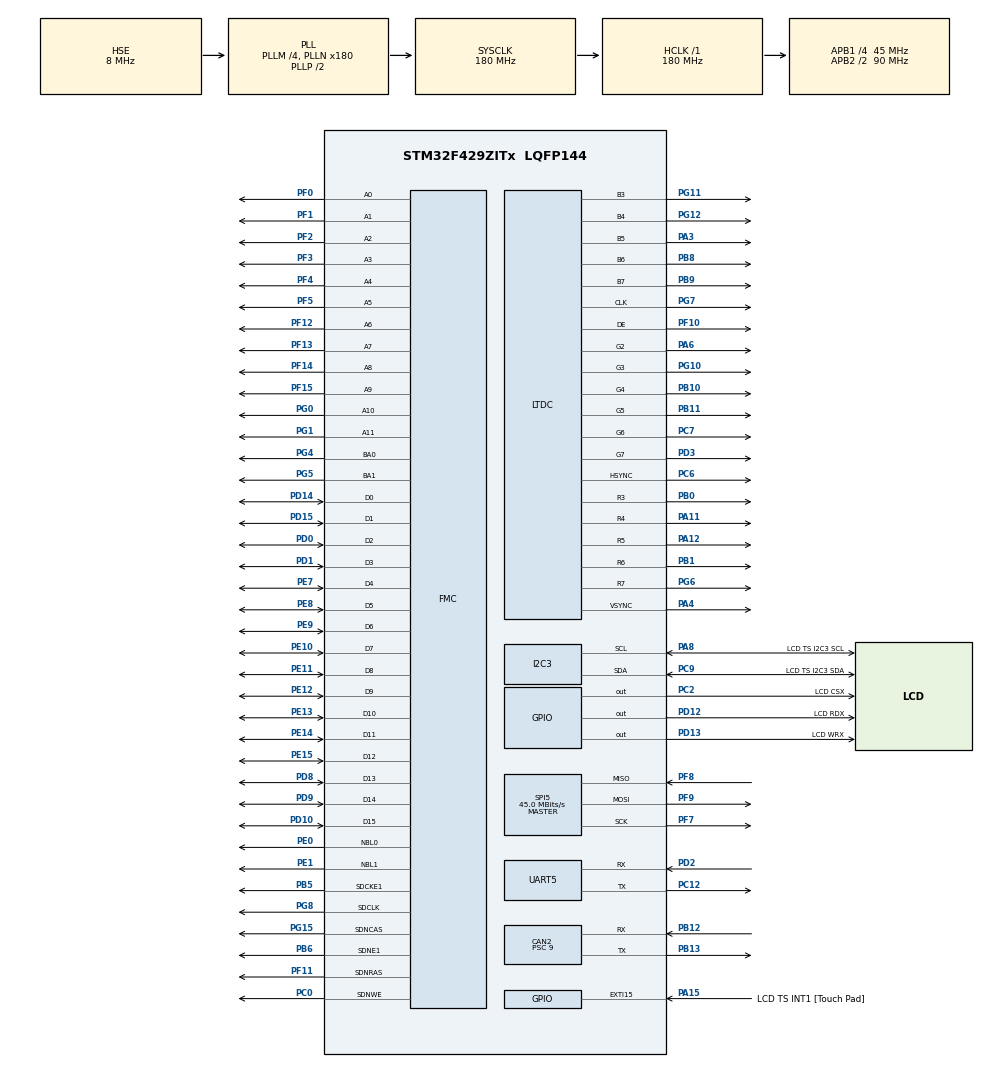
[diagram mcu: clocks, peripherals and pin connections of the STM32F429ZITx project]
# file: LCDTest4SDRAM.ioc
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SH.FMC_D7_DA7.0=FMC_D7,sd-16b-d1
PD12.GPIO_Label=LCD RDX
FMC.RCDDelay1=2
FMC.SDClockPeriod1=FMC_SDRAM_CLOCK_PERIOD_2
SH.FMC_A0.0=FMC_A0,12b-sda1
PB10.Mode=RGB565
PG8.Signal=FMC_SDCLK
PG4.Signal=FMC_A14_BA0
PC12.Signal=UART5_TX
PG0.Signal=FMC_A10
FMC.LoadToActiveDelay1=2
SH.FMC_D5_DA5.0=FMC_D5,sd-16b-d1
PB13.Signal=CAN2_TX
PG6.Mode=RGB565
RCC.SYSCLKSource=RCC_SYSCLKSOURCE_PLLCLK
SH.FMC_A15_BA1.0=FMC_BA1,FourSdramBanks1
SH.FMC_D9_DA9.0=FMC_D9,sd-16b-d1
PA4.Mode=RGB565
PF7.Signal=SPI5_SCK
SH.FMC_SDNWE.0=FMC_SDNWE,12b-sda1
PA15.GPIO_ModeDefaultEXTI=GPIO_MODE_IT_FALLING
SH.FMC_D11_DA11.0=FMC_D11,sd-16b-d1
RCC.APB2TimFreq_Value=180000000
PB6.Signal=FMC_SDNE1
PC7.Signal=LTDC_G6
PH1/OSC_OUT.Signal=RCC_OSC_OUT
PB6.Mode=SdramChipSelect2_1
PD0.Signal=FMC_D2_DA2
PD8.Signal=FMC_D13_DA13
PE1.Signal=FMC_NBL1
NVIC.EXTI15_10_IRQn=true\:15\:0\:true\:false\:true\:true\:true
FMC.SelfRefreshTime1=4
LTDC.PixelFormat_L0=LTDC_PIXEL_FORMAT_ARGB8888
PE9.Signal=FMC_D6_DA6
SH.FMC_A2.0=FMC_A2,12b-sda1
PC9.Mode=I2C
PF8.Mode=Full_Duplex_Master
PA8.Signal=I2C3_SCL
SH.FMC_D1_DA1.0=FMC_D1,sd-16b-d1
PF3.Signal=FMC_A3
PD3.Mode=RGB565
PE10.Signal=FMC_D7_DA7
LTDC.HSync=10
Mcu.Package=LQFP144
PB9.Signal=LTDC_B7
PB1.Signal=LTDC_R6
PD12.Signal=GPIO_Output
FMC.WriteRecoveryTime1=2
SH.FMC_A1.0=FMC_A1,12b-sda1
SPI5.CalculateBaudRate=45.0 MBits/s
RCC.APB2CLKDivider=RCC_HCLK_DIV2
SH.FMC_SDCLK.0=FMC_SDCLK,12b-sda1
LTDC.VSync=2
PF14.Signal=FMC_A8
RCC.APB1TimFreq_Value=90000000
VP_DMA2D_VS_DMA2D.Mode=DMA2D_Activate
FMC.RowCycleDelay2=6
PF10.Mode=RGB565
FMC.RowCycleDelay1=6
PB13.Mode=CAN_Activate
PD15.Signal=FMC_D1_DA1
SH.FMC_D3_DA3.0=FMC_D3,sd-16b-d1
SPI5.VirtualType=VM_MASTER
PG12.Signal=LTDC_B4
CAN2.CalculateBaudRate=250000
SH.FMC_A4.0=FMC_A4,12b-sda1
PG5.Signal=FMC_A15_BA1
SH.FMC_D10_DA10.0=FMC_D10,sd-16b-d1
PD3.Signal=LTDC_G7
PC6.Signal=LTDC_HSYNC
PC2.Signal=GPIO_Output
PD1.Signal=FMC_D3_DA3
UART5.VirtualMode=Asynchronous
PC0.Signal=FMC_SDNWE
RCC.APB1CLKDivider=RCC_HCLK_DIV4
PG10.Signal=LTDC_G3
LTDC.ImageWidth_L0=240
PD10.Signal=FMC_D15_DA15
PA3.Mode=RGB565
SH.FMC_A3.0=FMC_A3,12b-sda1
PA8.GPIO_Label=LCD TS I2C3 SCL
FMC.CASLatency1=FMC_SDRAM_CAS_LATENCY_3
PB11.Mode=RGB565
SH.FMC_D15_DA15.0=FMC_D15,sd-16b-d1
PC6.Mode=RGB565
PB10.Signal=LTDC_G4
PC12.Mode=Asynchronous
SH.FMC_A6.0=FMC_A6,12b-sda1
PE14.Signal=FMC_D11_DA11
PE15.Signal=FMC_D12_DA12
PE8.Signal=FMC_D5_DA5
PF13.Signal=FMC_A7
SH.FMC_SDNCAS.0=FMC_SDNCAS,12b-sda1
PA4.Signal=LTDC_VSYNC
PB5.Signal=FMC_SDCKE1
SH.FMC_A5.0=FMC_A5,12b-sda1
PG11.Mode=RGB565
LTDC.Alpha_L0=255
PA11.Signal=LTDC_R4
ProjectManager.HeapSize=0x200
PB1.Mode=RGB565
PF9.Signal=SPI5_MOSI
NVIC.PriorityGroup=NVIC_PRIORITYGROUP_4
PB8.Mode=RGB565
PA8.Mode=I2C
PF4.Signal=FMC_A4
PD2.Signal=UART5_RX
PB0.Signal=LTDC_R3
Mcu.Family=STM32F4
PA6.Mode=RGB565
SH.FMC_A8.0=FMC_A8,12b-sda1
RCC.CortexFreq_Value=180000000
PG6.Signal=LTDC_R7
NVIC.CAN2_RX0_IRQn=true\:0\:0\:false\:false\:true\:true\:true
SH.FMC_D14_DA14.0=FMC_D14,sd-16b-d1
LTDC.HBP=20
CAN2.CalculateTimeBit=4000.00
PC10.Signal=LTDC_R2
SH.FMC_NBL0.0=FMC_NBL0,Sd2ByteEnable1
SH.FMC_D6_DA6.0=FMC_D6,sd-16b-d1
PA11.Mode=RGB565
SH.FMC_A14_BA0.0=FMC_BA0,FourSdramBanks1
SH.FMC_A11.0=FMC_A11,12b-sda1
PB11.Signal=LTDC_G5
PG11.Signal=LTDC_B3
PG15.Signal=FMC_SDNCAS
ProjectManager.StackSize=0x400
PD13.Signal=GPIO_Output
PA15.GPIO_Label=LCD TS INT1 [Touch Pad]
SH.FMC_A7.0=FMC_A7,12b-sda1
PA12.Signal=LTDC_R5
PH0/OSC_IN.Mode=HSE-External-Oscillator
RCC.HCLKFreq_Value=180000000
SH.FMC_NBL1.0=FMC_NBL1,Sd2ByteEnable1
LTDC.WindowX1_L0=240
PF12.Signal=FMC_A6
SH.FMC_A10.0=FMC_A10,12b-sda1
RCC.AHBFreq_Value=180000000
RCC.HSE_VALUE=8000000
SH.FMC_D8_DA8.0=FMC_D8,sd-16b-d1
FMC.ExitSelfRefreshDelay1=7
FMC.RPDelay1=2
SH.FMC_D2_DA2.0=FMC_D2,sd-16b-d1
PF9.Mode=Full_Duplex_Master
PE13.Signal=FMC_D10_DA10
CAN2.Prescaler=9
PF11.Signal=FMC_SDNRAS
PB5.Mode=SdramChipSelect2_1
LTDC.HFP=10
FMC.ReadPipeDelay1=FMC_SDRAM_RPIPE_DELAY_1
SH.FMC_SDNRAS.0=FMC_SDNRAS,12b-sda1
DMA2D.ColorMode=DMA2D_OUTPUT_ARGB8888
LTDC.ActiveW=240
PH1/OSC_OUT.Mode=HSE-External-Oscillator
PD13.GPIO_Label=LCD WRX
SPI5.BaudRatePrescaler=SPI_BAUDRATEPRESCALER_2
PA6.Signal=LTDC_G2
PB12.Mode=CAN_Activate
SH.FMC_D0_DA0.0=FMC_D0,sd-16b-d1
CAN2.BS1=CAN_BS1_16TQ
CAN2.BS2=CAN_BS2_3TQ
SH.FMC_A9.0=FMC_A9,12b-sda1
PA15.Signal=GPXTI15
PF8.Signal=SPI5_MISO
SH.FMC_D4_DA4.0=FMC_D4,sd-16b-d1
RCC.PLLSAIN=60
PF5.Signal=FMC_A5
RCC.PLLSAIR=5
PF0.Signal=FMC_A0
PE7.Signal=FMC_D4_DA4
PD6.Signal=LTDC_B2
PC2.GPIO_Label=LCD CSX
PA3.Signal=LTDC_B5
RCC.PLLSourceVirtual=RCC_PLLSOURCE_HSE
LTDC.VFP=4
LTDC.WindowY1_L0=320
PG7.Signal=LTDC_CLK
PC9.GPIO_Label=LCD TS I2C3 SDA
PG1.Signal=FMC_A11
PG10.Mode=RGB565
PD9.Signal=FMC_D14_DA14
SPI5.Mode=SPI_MODE_MASTER
PF7.Mode=Full_Duplex_Master
ProjectManager.TargetToolchain=STM32CubeIDE
SH.FMC_D13_DA13.0=FMC_D13,sd-16b-d1
LTDC.ActiveH=320
PB9.Mode=RGB565
PF2.Signal=FMC_A2
PE11.Signal=FMC_D8_DA8
PG7.Mode=RGB565
RCC.LSE_VALUE=32768
PD2.Mode=Asynchronous
PB0.Mode=RGB565
board=custom
PG12.Mode=RGB565
RCC.VCOOutputFreq_Value=360000000
PH0/OSC_IN.Signal=RCC_OSC_IN
RCC.APB2Freq_Value=90000000
LTDC.Layers=0
PF10.Signal=LTDC_DE
CAN2.CalculateTimeQuantum=200.0
SH.FMC_D12_DA12.0=FMC_D12,sd-16b-d1
PF15.Signal=FMC_A9
PF1.Signal=FMC_A1
Mcu.Name=STM32F429ZITx
PE0.Signal=FMC_NBL0
PE12.Signal=FMC_D9_DA9
PD14.Signal=FMC_D0_DA0
RCC.48MHZClocksFreq_Value=90000000
RCC.SYSCLKFreq_VALUE=180000000
PA12.Mode=RGB565
SPI5.CRCCalculation=SPI_CRCCALCULATION_DISABLE
RCC.HSI_VALUE=16000000
RCC.PLLM=4
RCC.PLLN=180
PA15.GPIO_PuPd=GPIO_PULLUP
PB8.Signal=LTDC_B6
PC9.Signal=I2C3_SDA
PC7.Mode=RGB565
RCC.APB1Freq_Value=45000000
LTDC.ImageHeight_L0=320
DMA2D.Mode=DMA2D_R2M
PB12.Signal=CAN2_RX
SPI5.Direction=SPI_DIRECTION_2LINES

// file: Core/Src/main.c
/* USER CODE BEGIN Header */
/**
 ******************************************************************************
 * @file           : main.c
 * @brief          : Main program body
 ******************************************************************************
 * @attention
 *
 * <h2><center>&copy; Copyright (c) 2021 STMicroelectronics.
 * All rights reserved.</center></h2>
 *
 * This software component is licensed by ST under BSD 3-Clause license,
 * the "License"; You may not use this file except in compliance with the
 * License. You may obtain a copy of the License at:
 *                        opensource.org/licenses/BSD-3-Clause
 *
 ******************************************************************************
 */
/* USER CODE END Header */
#include "main.h"

/* USER CODE BEGIN Includes */
#include <stdio.h>
#include <string.h>

#include "extlib/stm32f429i_discovery_ts.h"
#include "extlib/stm32f429i_discovery_lcd.h"

/* USER CODE END Includes */

/* USER CODE BEGIN PD */
#define SDRAM_FRAME_BUFFER 0xD0000000

#define SDRAM_MODEREG_BURST_LENGTH_1             ((uint16_t)0x0000)
#define SDRAM_MODEREG_BURST_LENGTH_2             ((uint16_t)0x0001)
#define SDRAM_MODEREG_BURST_LENGTH_4             ((uint16_t)0x0002)
#define SDRAM_MODEREG_BURST_LENGTH_8             ((uint16_t)0x0004)
#define SDRAM_MODEREG_BURST_TYPE_SEQUENTIAL      ((uint16_t)0x0000)
#define SDRAM_MODEREG_BURST_TYPE_INTERLEAVED     ((uint16_t)0x0008)
#define SDRAM_MODEREG_CAS_LATENCY_2              ((uint16_t)0x0020)
#define SDRAM_MODEREG_CAS_LATENCY_3              ((uint16_t)0x0030)
#define SDRAM_MODEREG_OPERATING_MODE_STANDARD    ((uint16_t)0x0000)
#define SDRAM_MODEREG_WRITEBURST_MODE_PROGRAMMED ((uint16_t)0x0000)
#define SDRAM_MODEREG_WRITEBURST_MODE_SINGLE     ((uint16_t)0x0200)

/* USER CODE END PD */

CAN_HandleTypeDef hcan2;

DMA2D_HandleTypeDef hdma2d;

I2C_HandleTypeDef hi2c3;

LTDC_HandleTypeDef hltdc;

SPI_HandleTypeDef hspi5;

UART_HandleTypeDef huart5;

SDRAM_HandleTypeDef hsdram1;

void SystemClock_Config(void);
static void MX_GPIO_Init(void);
static void MX_CAN2_Init(void);
static void MX_UART5_Init(void);
static void MX_I2C3_Init(void);
static void MX_SPI5_Init(void);
static void MX_LTDC_Init(void);
static void MX_DMA2D_Init(void);
static void MX_FMC_Init(void);

/* USER CODE BEGIN 0 */
int __io_putchar(int ch)
{
    if(HAL_UART_Transmit(&huart5, (uint8_t *)&ch, 1, 10) != HAL_OK)
        return -1;
    return ch;
}

static uint16_t x, y;
void HAL_GPIO_EXTI_Callback(uint16_t GPIO_Pin)
{
    if(GPIO_Pin  == LCD_TS_INT1_Pin)
    {
        TS_StateTypeDef tp_state;
        BSP_TS_GetState(&tp_state);
        if(x != tp_state.X || y != tp_state.Y)
        {
            char buf[32] = {0, };

            if(tp_state.X > 240) tp_state.X = 240;
            if(tp_state.Y > 320) tp_state.Y = 320;

            sprintf(buf, "x = %d, y = %d", tp_state.X, tp_state.Y);
            // printf("%s\r\n", buf);
            BSP_LCD_Clear(LCD_COLOR_WHITE);

            BSP_LCD_SetFont(&Font20);
            BSP_LCD_DisplayStringAt(0, 120, (uint8_t *)buf, CENTER_MODE);
            x = tp_state.X;
            y = tp_state.Y;
        }
        BSP_TS_ITClear();
    }
}

/* USER CODE END 0 */

int main(void)
{

    /* MCU Configuration--------------------------------------------------------*/

    /* Reset of all peripherals, Initializes the Flash interface and the Systick. */
    HAL_Init();

    /* Configure the system clock */
    SystemClock_Config();

    /* Initialize all configured peripherals */
    MX_GPIO_Init();
    MX_CAN2_Init();
    MX_UART5_Init();
    MX_I2C3_Init();
    MX_SPI5_Init();
    MX_LTDC_Init();
    MX_DMA2D_Init();
    MX_FMC_Init();
    /* USER CODE BEGIN 2 */
    BSP_LCD_Init(hltdc, hdma2d);
    BSP_LCD_LayerDefaultInit(LCD_BACKGROUND_LAYER, (uint32_t)SDRAM_FRAME_BUFFER);
    BSP_LCD_SelectLayer(LCD_BACKGROUND_LAYER);
    BSP_LCD_DisplayOn();
    BSP_LCD_Clear(LCD_COLOR_WHITE);

    BSP_LCD_SetBackColor(LCD_COLOR_WHITE);
    BSP_LCD_SetTextColor(LCD_COLOR_BLACK);
    BSP_LCD_SetFont(&LCD_DEFAULT_FONT);
    BSP_LCD_DisplayStringAt(0, 150, (uint8_t *)"LCD Test1", CENTER_MODE);
    BSP_LCD_DisplayStringAt(0, 180, (uint8_t *)"LCD Test2", CENTER_MODE);

    BSP_TS_Init(240, 320);
    BSP_TS_ITConfig();
    /* USER CODE END 2 */

    /* Infinite loop */
    while (1)
    {

    }
}

void SystemClock_Config(void)
{
    RCC_OscInitTypeDef RCC_OscInitStruct = {0};
    RCC_ClkInitTypeDef RCC_ClkInitStruct = {0};
    RCC_PeriphCLKInitTypeDef PeriphClkInitStruct = {0};

    /** Configure the main internal regulator output voltage
    */
    __HAL_RCC_PWR_CLK_ENABLE();
    __HAL_PWR_VOLTAGESCALING_CONFIG(PWR_REGULATOR_VOLTAGE_SCALE1);
    /** Initializes the RCC Oscillators according to the specified parameters
     * in the RCC_OscInitTypeDef structure.
     */
    RCC_OscInitStruct.OscillatorType = RCC_OSCILLATORTYPE_HSE;
    RCC_OscInitStruct.HSEState = RCC_HSE_ON;
    RCC_OscInitStruct.PLL.PLLState = RCC_PLL_ON;
    RCC_OscInitStruct.PLL.PLLSource = RCC_PLLSOURCE_HSE;
    RCC_OscInitStruct.PLL.PLLM = 4;
    RCC_OscInitStruct.PLL.PLLN = 180;
    RCC_OscInitStruct.PLL.PLLP = RCC_PLLP_DIV2;
    RCC_OscInitStruct.PLL.PLLQ = 4;
    if (HAL_RCC_OscConfig(&RCC_OscInitStruct) != HAL_OK)
    {
        Error_Handler();
    }
    /** Activate the Over-Drive mode
    */
    if (HAL_PWREx_EnableOverDrive() != HAL_OK)
    {
        Error_Handler();
    }
    /** Initializes the CPU, AHB and APB buses clocks
    */
    RCC_ClkInitStruct.ClockType = RCC_CLOCKTYPE_HCLK|RCC_CLOCKTYPE_SYSCLK
        |RCC_CLOCKTYPE_PCLK1|RCC_CLOCKTYPE_PCLK2;
    RCC_ClkInitStruct.SYSCLKSource = RCC_SYSCLKSOURCE_PLLCLK;
    RCC_ClkInitStruct.AHBCLKDivider = RCC_SYSCLK_DIV1;
    RCC_ClkInitStruct.APB1CLKDivider = RCC_HCLK_DIV4;
    RCC_ClkInitStruct.APB2CLKDivider = RCC_HCLK_DIV2;

    if (HAL_RCC_ClockConfig(&RCC_ClkInitStruct, FLASH_LATENCY_5) != HAL_OK)
    {
        Error_Handler();
    }
    PeriphClkInitStruct.PeriphClockSelection = RCC_PERIPHCLK_LTDC;
    PeriphClkInitStruct.PLLSAI.PLLSAIN = 60;
    PeriphClkInitStruct.PLLSAI.PLLSAIR = 5;
    PeriphClkInitStruct.PLLSAIDivR = RCC_PLLSAIDIVR_2;
    if (HAL_RCCEx_PeriphCLKConfig(&PeriphClkInitStruct) != HAL_OK)
    {
        Error_Handler();
    }
}

static void MX_CAN2_Init(void)
{

    hcan2.Instance = CAN2;
    hcan2.Init.Prescaler = 9;
    hcan2.Init.Mode = CAN_MODE_NORMAL;
    hcan2.Init.SyncJumpWidth = CAN_SJW_1TQ;
    hcan2.Init.TimeSeg1 = CAN_BS1_16TQ;
    hcan2.Init.TimeSeg2 = CAN_BS2_3TQ;
    hcan2.Init.TimeTriggeredMode = DISABLE;
    hcan2.Init.AutoBusOff = DISABLE;
    hcan2.Init.AutoWakeUp = DISABLE;
    hcan2.Init.AutoRetransmission = DISABLE;
    hcan2.Init.ReceiveFifoLocked = DISABLE;
    hcan2.Init.TransmitFifoPriority = DISABLE;
    if (HAL_CAN_Init(&hcan2) != HAL_OK)
    {
        Error_Handler();
    }

}

static void MX_DMA2D_Init(void)
{

    hdma2d.Instance = DMA2D;
    hdma2d.Init.Mode = DMA2D_R2M;
    hdma2d.Init.ColorMode = DMA2D_OUTPUT_ARGB8888;
    hdma2d.Init.OutputOffset = 0;
    if (HAL_DMA2D_Init(&hdma2d) != HAL_OK)
    {
        Error_Handler();
    }

}

static void MX_I2C3_Init(void)
{

    hi2c3.Instance = I2C3;
    hi2c3.Init.ClockSpeed = 100000;
    hi2c3.Init.DutyCycle = I2C_DUTYCYCLE_2;
    hi2c3.Init.OwnAddress1 = 0;
    hi2c3.Init.AddressingMode = I2C_ADDRESSINGMODE_7BIT;
    hi2c3.Init.DualAddressMode = I2C_DUALADDRESS_DISABLE;
    hi2c3.Init.OwnAddress2 = 0;
    hi2c3.Init.GeneralCallMode = I2C_GENERALCALL_DISABLE;
    hi2c3.Init.NoStretchMode = I2C_NOSTRETCH_DISABLE;
    if (HAL_I2C_Init(&hi2c3) != HAL_OK)
    {
        Error_Handler();
    }
    /** Configure Analogue filter
    */
    if (HAL_I2CEx_ConfigAnalogFilter(&hi2c3, I2C_ANALOGFILTER_ENABLE) != HAL_OK)
    {
        Error_Handler();
    }
    /** Configure Digital filter
    */
    if (HAL_I2CEx_ConfigDigitalFilter(&hi2c3, 0) != HAL_OK)
    {
        Error_Handler();
    }

}

static void MX_LTDC_Init(void)
{

    LTDC_LayerCfgTypeDef pLayerCfg = {0};

    hltdc.Instance = LTDC;
    hltdc.Init.HSPolarity = LTDC_HSPOLARITY_AL;
    hltdc.Init.VSPolarity = LTDC_VSPOLARITY_AL;
    hltdc.Init.DEPolarity = LTDC_DEPOLARITY_AL;
    hltdc.Init.PCPolarity = LTDC_PCPOLARITY_IPC;
    hltdc.Init.HorizontalSync = 9;
    hltdc.Init.VerticalSync = 1;
    hltdc.Init.AccumulatedHBP = 29;
    hltdc.Init.AccumulatedVBP = 3;
    hltdc.Init.AccumulatedActiveW = 269;
    hltdc.Init.AccumulatedActiveH = 323;
    hltdc.Init.TotalWidth = 279;
    hltdc.Init.TotalHeigh = 327;
    hltdc.Init.Backcolor.Blue = 0;
    hltdc.Init.Backcolor.Green = 0;
    hltdc.Init.Backcolor.Red = 0;
    if (HAL_LTDC_Init(&hltdc) != HAL_OK)
    {
        Error_Handler();
    }
    pLayerCfg.WindowX0 = 0;
    pLayerCfg.WindowX1 = 240;
    pLayerCfg.WindowY0 = 0;
    pLayerCfg.WindowY1 = 320;
    pLayerCfg.PixelFormat = LTDC_PIXEL_FORMAT_ARGB8888;
    pLayerCfg.Alpha = 255;
    pLayerCfg.Alpha0 = 0;
    pLayerCfg.BlendingFactor1 = LTDC_BLENDING_FACTOR1_CA;
    pLayerCfg.BlendingFactor2 = LTDC_BLENDING_FACTOR2_CA;
    pLayerCfg.FBStartAdress = 0;
    pLayerCfg.ImageWidth = 240;
    pLayerCfg.ImageHeight = 320;
    pLayerCfg.Backcolor.Blue = 0;
    pLayerCfg.Backcolor.Green = 0;
    pLayerCfg.Backcolor.Red = 0;
    if (HAL_LTDC_ConfigLayer(&hltdc, &pLayerCfg, 0) != HAL_OK)
    {
        Error_Handler();
    }

}

static void MX_SPI5_Init(void)
{

    /* SPI5 parameter configuration*/
    hspi5.Instance = SPI5;
    hspi5.Init.Mode = SPI_MODE_MASTER;
    hspi5.Init.Direction = SPI_DIRECTION_2LINES;
    hspi5.Init.DataSize = SPI_DATASIZE_8BIT;
    hspi5.Init.CLKPolarity = SPI_POLARITY_LOW;
    hspi5.Init.CLKPhase = SPI_PHASE_1EDGE;
    hspi5.Init.NSS = SPI_NSS_SOFT;
    hspi5.Init.BaudRatePrescaler = SPI_BAUDRATEPRESCALER_2;
    hspi5.Init.FirstBit = SPI_FIRSTBIT_MSB;
    hspi5.Init.TIMode = SPI_TIMODE_DISABLE;
    hspi5.Init.CRCCalculation = SPI_CRCCALCULATION_DISABLE;
    hspi5.Init.CRCPolynomial = 10;
    if (HAL_SPI_Init(&hspi5) != HAL_OK)
    {
        Error_Handler();
    }

}

static void MX_UART5_Init(void)
{

    huart5.Instance = UART5;
    huart5.Init.BaudRate = 115200;
    huart5.Init.WordLength = UART_WORDLENGTH_8B;
    huart5.Init.StopBits = UART_STOPBITS_1;
    huart5.Init.Parity = UART_PARITY_NONE;
    huart5.Init.Mode = UART_MODE_TX_RX;
    huart5.Init.HwFlowCtl = UART_HWCONTROL_NONE;
    huart5.Init.OverSampling = UART_OVERSAMPLING_16;
    if (HAL_UART_Init(&huart5) != HAL_OK)
    {
        Error_Handler();
    }

}

/* FMC initialization function */
static void MX_FMC_Init(void)
{

    FMC_SDRAM_TimingTypeDef SdramTiming = {0};

    /** Perform the SDRAM1 memory initialization sequence
    */
    hsdram1.Instance = FMC_SDRAM_DEVICE;
    /* hsdram1.Init */
    hsdram1.Init.SDBank = FMC_SDRAM_BANK2;
    hsdram1.Init.ColumnBitsNumber = FMC_SDRAM_COLUMN_BITS_NUM_8;
    hsdram1.Init.RowBitsNumber = FMC_SDRAM_ROW_BITS_NUM_12;
    hsdram1.Init.MemoryDataWidth = FMC_SDRAM_MEM_BUS_WIDTH_16;
    hsdram1.Init.InternalBankNumber = FMC_SDRAM_INTERN_BANKS_NUM_4;
    hsdram1.Init.CASLatency = FMC_SDRAM_CAS_LATENCY_3;
    hsdram1.Init.WriteProtection = FMC_SDRAM_WRITE_PROTECTION_DISABLE;
    hsdram1.Init.SDClockPeriod = FMC_SDRAM_CLOCK_PERIOD_2;
    hsdram1.Init.ReadBurst = FMC_SDRAM_RBURST_DISABLE;
    hsdram1.Init.ReadPipeDelay = FMC_SDRAM_RPIPE_DELAY_1;
    /* SdramTiming */
    SdramTiming.LoadToActiveDelay = 2;
    SdramTiming.ExitSelfRefreshDelay = 7;
    SdramTiming.SelfRefreshTime = 4;
    SdramTiming.RowCycleDelay = 6;
    SdramTiming.WriteRecoveryTime = 2;
    SdramTiming.RPDelay = 2;
    SdramTiming.RCDDelay = 2;

    if (HAL_SDRAM_Init(&hsdram1, &SdramTiming) != HAL_OK)
    {
        Error_Handler( );
    }
    else
    {
        __IO uint32_t tmpmrd =0;
        FMC_SDRAM_CommandTypeDef Command;

        /* Step 1:  Configure a clock configuration enable command */
        Command.CommandMode             = FMC_SDRAM_CMD_CLK_ENABLE;
        Command.CommandTarget           = FMC_SDRAM_CMD_TARGET_BANK2;
        Command.AutoRefreshNumber       = 1;
        Command.ModeRegisterDefinition  = 0;

        /* Send the command */
        HAL_SDRAM_SendCommand(&hsdram1, &Command, 0x1000);

        /* Step 2: Insert 100 us minimum delay */
        /* Inserted delay is equal to 1 ms due to systick time base unit (ms) */
        HAL_Delay(100);

        /* Step 3: Configure a PALL (precharge all) command */
        Command.CommandMode             = FMC_SDRAM_CMD_PALL;
        Command.CommandTarget           = FMC_SDRAM_CMD_TARGET_BANK2;
        Command.AutoRefreshNumber       = 1;
        Command.ModeRegisterDefinition  = 0;

        /* Send the command */
        HAL_SDRAM_SendCommand(&hsdram1, &Command, 0x1000);

        /* Step 4: Configure an Auto Refresh command */
        Command.CommandMode             = FMC_SDRAM_CMD_AUTOREFRESH_MODE;
        Command.CommandTarget           = FMC_SDRAM_CMD_TARGET_BANK2;
        Command.AutoRefreshNumber       = 4;
        Command.ModeRegisterDefinition  = 0;

        /* Send the command */
        HAL_SDRAM_SendCommand(&hsdram1, &Command, 0x1000);

        /* Step 5: Program the external memory mode register */
        tmpmrd = (uint32_t)SDRAM_MODEREG_BURST_LENGTH_1          |
            SDRAM_MODEREG_BURST_TYPE_SEQUENTIAL   |
            SDRAM_MODEREG_CAS_LATENCY_3           |
            SDRAM_MODEREG_OPERATING_MODE_STANDARD |
            SDRAM_MODEREG_WRITEBURST_MODE_SINGLE;

        Command.CommandMode             = FMC_SDRAM_CMD_LOAD_MODE;
        Command.CommandTarget           = FMC_SDRAM_CMD_TARGET_BANK2;
        Command.AutoRefreshNumber       = 1;
        Command.ModeRegisterDefinition  = tmpmrd;

        /* Send the command */
        HAL_SDRAM_SendCommand(&hsdram1, &Command, 0x1000);

        /* Step 6: Set the refresh rate counter */
        /**
         *
         * Set the device refresh rate
         *
         *  refresh rate  = refresh period / number of rows
         *  refresh rate  = 64ms / 4096 = 15.62us
         *  refresh count = (refresh rate x SDRAM clock frequency) - 20
         *  refresh count = 15.62us x 90MHz - 20 = 1385.xx
         *
         */
        HAL_SDRAM_ProgramRefreshRate(&hsdram1, 1386);
    }
    /* USER CODE END FMC_Init 2 */
}

static void MX_GPIO_Init(void)
{
    GPIO_InitTypeDef GPIO_InitStruct = {0};

    /* GPIO Ports Clock Enable */
    __HAL_RCC_GPIOF_CLK_ENABLE();
    __HAL_RCC_GPIOH_CLK_ENABLE();
    __HAL_RCC_GPIOC_CLK_ENABLE();
    __HAL_RCC_GPIOA_CLK_ENABLE();
    __HAL_RCC_GPIOB_CLK_ENABLE();
    __HAL_RCC_GPIOG_CLK_ENABLE();
    __HAL_RCC_GPIOE_CLK_ENABLE();
    __HAL_RCC_GPIOD_CLK_ENABLE();

    /*Configure GPIO pin Output Level */
    HAL_GPIO_WritePin(LCD_CSX_GPIO_Port, LCD_CSX_Pin, GPIO_PIN_RESET);

    /*Configure GPIO pin Output Level */
    HAL_GPIO_WritePin(GPIOD, LCD_RDX_Pin|LCD_WRX_Pin, GPIO_PIN_RESET);

    /*Configure GPIO pin : LCD_CSX_Pin */
    GPIO_InitStruct.Pin = LCD_CSX_Pin;
    GPIO_InitStruct.Mode = GPIO_MODE_OUTPUT_PP;
    GPIO_InitStruct.Pull = GPIO_NOPULL;
    GPIO_InitStruct.Speed = GPIO_SPEED_FREQ_LOW;
    HAL_GPIO_Init(LCD_CSX_GPIO_Port, &GPIO_InitStruct);

    /*Configure GPIO pins : LCD_RDX_Pin LCD_WRX_Pin */
    GPIO_InitStruct.Pin = LCD_RDX_Pin|LCD_WRX_Pin;
    GPIO_InitStruct.Mode = GPIO_MODE_OUTPUT_PP;
    GPIO_InitStruct.Pull = GPIO_NOPULL;
    GPIO_InitStruct.Speed = GPIO_SPEED_FREQ_LOW;
    HAL_GPIO_Init(GPIOD, &GPIO_InitStruct);

    /*Configure GPIO pin : LCD_TS_INT1_Pin */
    GPIO_InitStruct.Pin = LCD_TS_INT1_Pin;
    GPIO_InitStruct.Mode = GPIO_MODE_IT_FALLING;
    GPIO_InitStruct.Pull = GPIO_PULLUP;
    HAL_GPIO_Init(LCD_TS_INT1_GPIO_Port, &GPIO_InitStruct);

    /* EXTI interrupt init*/
    HAL_NVIC_SetPriority(EXTI15_10_IRQn, 15, 0);
    HAL_NVIC_EnableIRQ(EXTI15_10_IRQn);

}

void Error_Handler(void)
{
    __disable_irq();
    while (1)
    {
    }
}

/************************ (C) COPYRIGHT STMicroelectronics *****END OF FILE****/
